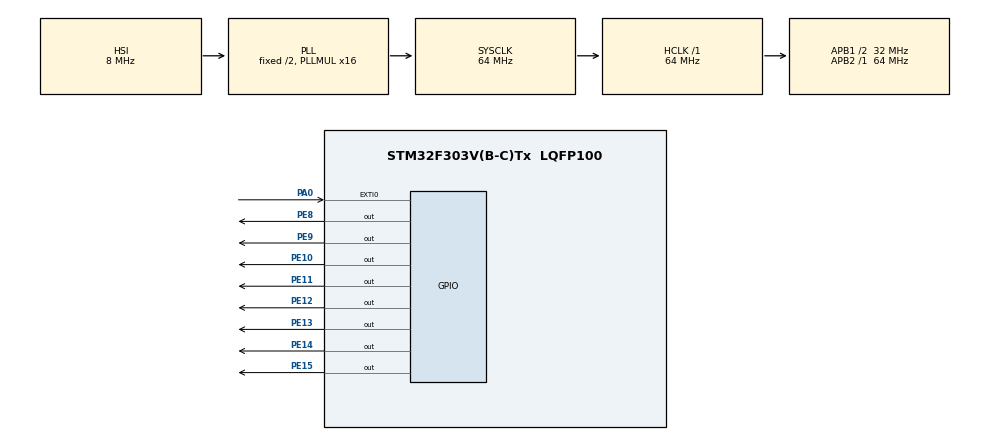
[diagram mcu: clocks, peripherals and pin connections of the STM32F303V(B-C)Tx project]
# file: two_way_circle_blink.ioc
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Mcu.Family=STM32F3
Mcu.Name=STM32F303V(B-C)Tx
Mcu.Package=LQFP100
NVIC.EXTI0_IRQn=true\:0\:0\:false\:false\:true
NVIC.PriorityGroup=NVIC_PRIORITYGROUP_4
PA0.Signal=GPXTI0
PE10.Signal=GPIO_Output
PE11.Signal=GPIO_Output
PE12.Signal=GPIO_Output
PE13.Signal=GPIO_Output
PE14.Signal=GPIO_Output
PE15.Signal=GPIO_Output
PE8.Signal=GPIO_Output
PE9.Signal=GPIO_Output
ProjectManager.HeapSize=0x200
ProjectManager.StackSize=0x400
ProjectManager.TargetToolchain=SW4STM32
RCC.AHBFreq_Value=64000000
RCC.APB1CLKDivider=RCC_HCLK_DIV2
RCC.APB1Freq_Value=32000000
RCC.APB1TimFreq_Value=64000000
RCC.APB2Freq_Value=64000000
RCC.APB2TimFreq_Value=64000000
RCC.CortexFreq_Value=64000000
RCC.HCLKFreq_Value=64000000
RCC.HSE_VALUE=8000000
RCC.HSI_VALUE=8000000
RCC.LSE_VALUE=32768
RCC.PLLMUL=RCC_PLL_MUL16
RCC.SYSCLKFreq_VALUE=64000000
RCC.SYSCLKSourceVirtual=RCC_SYSCLKSOURCE_PLLCLK
RCC.USBFreq_Value=64000000
board=two_way_circle_blink

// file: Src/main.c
/**
  ******************************************************************************
  * File Name          : main.c
  * Description        : Main program body
  ******************************************************************************
  *
  * COPYRIGHT(c) 2016 STMicroelectronics
  *
  * Redistribution and use in source and binary forms, with or without modification,
  * are permitted provided that the following conditions are met:
  *   1. Redistributions of source code must retain the above copyright notice,
  *      this list of conditions and the following disclaimer.
  *   2. Redistributions in binary form must reproduce the above copyright notice,
  *      this list of conditions and the following disclaimer in the documentation
  *      and/or other materials provided with the distribution.
  *   3. Neither the name of STMicroelectronics nor the names of its contributors
  *      may be used to endorse or promote products derived from this software
  *      without specific prior written permission.
  *
  * THIS SOFTWARE IS PROVIDED BY THE COPYRIGHT HOLDERS AND CONTRIBUTORS "AS IS"
  * AND ANY EXPRESS OR IMPLIED WARRANTIES, INCLUDING, BUT NOT LIMITED TO, THE
  * IMPLIED WARRANTIES OF MERCHANTABILITY AND FITNESS FOR A PARTICULAR PURPOSE ARE
  * DISCLAIMED. IN NO EVENT SHALL THE COPYRIGHT HOLDER OR CONTRIBUTORS BE LIABLE
  * FOR ANY DIRECT, INDIRECT, INCIDENTAL, SPECIAL, EXEMPLARY, OR CONSEQUENTIAL
  * DAMAGES (INCLUDING, BUT NOT LIMITED TO, PROCUREMENT OF SUBSTITUTE GOODS OR
  * SERVICES; LOSS OF USE, DATA, OR PROFITS; OR BUSINESS INTERRUPTION) HOWEVER
  * CAUSED AND ON ANY THEORY OF LIABILITY, WHETHER IN CONTRACT, STRICT LIABILITY,
  * OR TORT (INCLUDING NEGLIGENCE OR OTHERWISE) ARISING IN ANY WAY OUT OF THE USE
  * OF THIS SOFTWARE, EVEN IF ADVISED OF THE POSSIBILITY OF SUCH DAMAGE.
  *
  ******************************************************************************
  */
#include "stm32f3xx_hal.h"
#include "gpio.h"

/* USER CODE BEGIN PV */
/* Private variables ---------------------------------------------------------*/

/* USER CODE END PV */

void SystemClock_Config(void);
void Error_Handler(void);

/* USER CODE BEGIN PFP */
/* Private function prototypes -----------------------------------------------*/
volatile int pressed = 0;
void HAL_GPIO_EXTI_Callback(uint16_t GPIO_Pin)
{
 if( GPIO_Pin == GPIO_PIN_0)
 {
  static uint32_t last_change_tick;
  if( HAL_GetTick() - last_change_tick < 50 )
  {
   return;
  }
  last_change_tick = HAL_GetTick();
  ++pressed;
 }
}

/* USER CODE END PFP */

int main(void)
{

  /* MCU Configuration----------------------------------------------------------*/

  /* Reset of all peripherals, Initializes the Flash interface and the Systick. */
  HAL_Init();

  /* Configure the system clock */
  SystemClock_Config();

  /* Initialize all configured peripherals */
  MX_GPIO_Init();

  /* Infinite loop */
  /* USER CODE BEGIN WHILE */
  int i = 0;
  while (1)
  {
	  HAL_GPIO_WritePin(GPIOE, GPIO_PIN_8, i % 8 == 0 );
	  HAL_GPIO_WritePin(GPIOE, GPIO_PIN_9, i % 8 == 1 );
	  HAL_GPIO_WritePin(GPIOE, GPIO_PIN_10, i % 8 == 2 );
	  HAL_GPIO_WritePin(GPIOE, GPIO_PIN_11, i % 8 == 3 );
	  HAL_GPIO_WritePin(GPIOE, GPIO_PIN_12, i % 8 == 4 );
	  HAL_GPIO_WritePin(GPIOE, GPIO_PIN_13, i % 8 == 5 );
	  HAL_GPIO_WritePin(GPIOE, GPIO_PIN_14, i % 8 == 6 );
	  HAL_GPIO_WritePin(GPIOE, GPIO_PIN_15, i % 8 == 7 );
	  HAL_Delay(1600);

	  HAL_GPIO_WritePin(GPIOE, GPIO_PIN_8, GPIO_PIN_RESET );
	  HAL_GPIO_WritePin(GPIOE, GPIO_PIN_9, GPIO_PIN_RESET );
	  HAL_GPIO_WritePin(GPIOE, GPIO_PIN_10, GPIO_PIN_RESET );
	  HAL_GPIO_WritePin(GPIOE, GPIO_PIN_11, GPIO_PIN_RESET );
	  HAL_GPIO_WritePin(GPIOE, GPIO_PIN_12, GPIO_PIN_RESET );
	  HAL_GPIO_WritePin(GPIOE, GPIO_PIN_13, GPIO_PIN_RESET );
	  HAL_GPIO_WritePin(GPIOE, GPIO_PIN_14, GPIO_PIN_RESET);
	  HAL_GPIO_WritePin(GPIOE, GPIO_PIN_15, GPIO_PIN_RESET );

	  if (pressed % 2 == 0) {
		  ++i;
	  } else {
		  --i;
	  }
	  if ( i < 0 ) {
		  i += 8;
	  }

    }

  }

/** System Clock Configuration
*/
void SystemClock_Config(void)
{

  RCC_OscInitTypeDef RCC_OscInitStruct;
  RCC_ClkInitTypeDef RCC_ClkInitStruct;

  RCC_OscInitStruct.OscillatorType = RCC_OSCILLATORTYPE_HSI;
  RCC_OscInitStruct.HSIState = RCC_HSI_ON;
  RCC_OscInitStruct.HSICalibrationValue = 16;
  RCC_OscInitStruct.PLL.PLLState = RCC_PLL_ON;
  RCC_OscInitStruct.PLL.PLLSource = RCC_PLLSOURCE_HSI;
  RCC_OscInitStruct.PLL.PLLMUL = RCC_PLL_MUL16;
  if (HAL_RCC_OscConfig(&RCC_OscInitStruct) != HAL_OK)
  {
    Error_Handler();
  }

  RCC_ClkInitStruct.ClockType = RCC_CLOCKTYPE_HCLK|RCC_CLOCKTYPE_SYSCLK
                              |RCC_CLOCKTYPE_PCLK1|RCC_CLOCKTYPE_PCLK2;
  RCC_ClkInitStruct.SYSCLKSource = RCC_SYSCLKSOURCE_PLLCLK;
  RCC_ClkInitStruct.AHBCLKDivider = RCC_SYSCLK_DIV1;
  RCC_ClkInitStruct.APB1CLKDivider = RCC_HCLK_DIV2;
  RCC_ClkInitStruct.APB2CLKDivider = RCC_HCLK_DIV1;
  if (HAL_RCC_ClockConfig(&RCC_ClkInitStruct, FLASH_LATENCY_2) != HAL_OK)
  {
    Error_Handler();
  }

  HAL_SYSTICK_Config(HAL_RCC_GetHCLKFreq()/1000);

  HAL_SYSTICK_CLKSourceConfig(SYSTICK_CLKSOURCE_HCLK);

  /* SysTick_IRQn interrupt configuration */
  HAL_NVIC_SetPriority(-1, 0, 0);
}

void Error_Handler(void)
{
  while(1)
  {
  }
}

/************************ (C) COPYRIGHT STMicroelectronics *****END OF FILE****/
